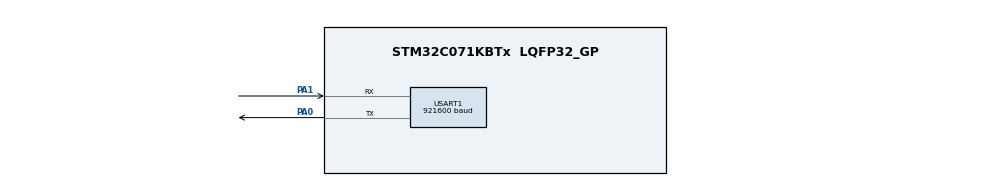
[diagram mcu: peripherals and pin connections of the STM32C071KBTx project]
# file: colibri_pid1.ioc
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Mcu.Family=STM32C0
Mcu.Name=STM32C071KBTx
Mcu.Package=LQFP32_GP
PA0.Mode=Asynchronous
PA0.Signal=USART1_TX
PA1.Mode=Asynchronous
PA1.Signal=USART1_RX
PA13.Mode=Serial_Wire
PA13.Signal=DEBUG_SWDIO
PA14-BOOT0.Mode=Serial_Wire
PA14-BOOT0.Signal=DEBUG_SWCLK
ProjectManager.HeapSize=0x200
ProjectManager.StackSize=0x400
ProjectManager.TargetToolchain=STM32CubeIDE
RCC.ADCFreq_Value=48000000
RCC.AHBFreq_Value=48000000
RCC.CortexFreq_Value=48000000
RCC.EXTERNAL_CLOCK_VALUE=12288000
RCC.HCLKFreq_Value=48000000
RCC.HSE_VALUE=8000000
RCC.HSI48_VALUE=48000000
RCC.HSISYSCLKDivider=RCC_HSI_DIV1
RCC.HSI_VALUE=48000000
RCC.LSE_VALUE=32768
RCC.SYSCLKFreq_VALUE=48000000
USART1.BaudRate=921600
USART1.VirtualMode-Asynchronous=VM_ASYNC
board=custom

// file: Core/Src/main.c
/* USER CODE BEGIN Header */
/**
  ******************************************************************************
  * @file           : main.c
  * @brief          : Main program body
  ******************************************************************************
  * @attention
  *
  * Copyright (c) 2026 STM32World <lth@stm32world.com>
  * All rights reserved.
  *
  * This software is licensed under terms that can be found in the LICENSE file
  * in the root directory of this software component.
  * If no LICENSE file comes with this software, it is provided AS-IS.
  *
  ******************************************************************************
  */
/* USER CODE END Header */
#include "main.h"

/* USER CODE BEGIN Includes */
#include <stdio.h>
/* USER CODE END Includes */

UART_HandleTypeDef huart1;

void SystemClock_Config(void);
static void MX_GPIO_Init(void);
static void MX_USART1_UART_Init(void);

int main(void)
{

  /* MCU Configuration--------------------------------------------------------*/

  /* Reset of all peripherals, Initializes the Flash interface and the Systick. */
  HAL_Init();

  /* Configure the system clock */
  SystemClock_Config();

  /* Initialize all configured peripherals */
  MX_GPIO_Init();
  MX_USART1_UART_Init();
  /* USER CODE BEGIN 2 */

  printf("Starting colibri pid1\n");

  /* USER CODE END 2 */

  /* Infinite loop */
  /* USER CODE BEGIN WHILE */

  uint32_t now, loop_cnt = 0, next_tick = 1000;

  while (1) {

      now = uwTick;

      if (now >= next_tick) {

          printf("Tick %lu (loop = %lu)\n", now / 1000, loop_cnt);

          loop_cnt = 0;
          next_tick = now + 1000;

      }

      ++loop_cnt;

    /* USER CODE END WHILE */

  }
}

void SystemClock_Config(void)
{
  RCC_OscInitTypeDef RCC_OscInitStruct = {0};
  RCC_ClkInitTypeDef RCC_ClkInitStruct = {0};

  __HAL_FLASH_SET_LATENCY(FLASH_LATENCY_1);

  /** Initializes the RCC Oscillators according to the specified parameters
  * in the RCC_OscInitTypeDef structure.
  */
  RCC_OscInitStruct.OscillatorType = RCC_OSCILLATORTYPE_HSI;
  RCC_OscInitStruct.HSIState = RCC_HSI_ON;
  RCC_OscInitStruct.HSIDiv = RCC_HSI_DIV1;
  RCC_OscInitStruct.HSICalibrationValue = RCC_HSICALIBRATION_DEFAULT;
  if (HAL_RCC_OscConfig(&RCC_OscInitStruct) != HAL_OK)
  {
    Error_Handler();
  }

  /** Initializes the CPU, AHB and APB buses clocks
  */
  RCC_ClkInitStruct.ClockType = RCC_CLOCKTYPE_HCLK|RCC_CLOCKTYPE_SYSCLK
                              |RCC_CLOCKTYPE_PCLK1;
  RCC_ClkInitStruct.SYSCLKSource = RCC_SYSCLKSOURCE_HSI;
  RCC_ClkInitStruct.SYSCLKDivider = RCC_SYSCLK_DIV1;
  RCC_ClkInitStruct.AHBCLKDivider = RCC_HCLK_DIV1;
  RCC_ClkInitStruct.APB1CLKDivider = RCC_APB1_DIV1;

  if (HAL_RCC_ClockConfig(&RCC_ClkInitStruct, FLASH_LATENCY_1) != HAL_OK)
  {
    Error_Handler();
  }
}

static void MX_USART1_UART_Init(void)
{

  huart1.Instance = USART1;
  huart1.Init.BaudRate = 921600;
  huart1.Init.WordLength = UART_WORDLENGTH_8B;
  huart1.Init.StopBits = UART_STOPBITS_1;
  huart1.Init.Parity = UART_PARITY_NONE;
  huart1.Init.Mode = UART_MODE_TX_RX;
  huart1.Init.HwFlowCtl = UART_HWCONTROL_NONE;
  huart1.Init.OverSampling = UART_OVERSAMPLING_16;
  huart1.Init.OneBitSampling = UART_ONE_BIT_SAMPLE_DISABLE;
  huart1.Init.ClockPrescaler = UART_PRESCALER_DIV1;
  huart1.AdvancedInit.AdvFeatureInit = UART_ADVFEATURE_NO_INIT;
  if (HAL_UART_Init(&huart1) != HAL_OK)
  {
    Error_Handler();
  }
  if (HAL_UARTEx_SetTxFifoThreshold(&huart1, UART_TXFIFO_THRESHOLD_1_8) != HAL_OK)
  {
    Error_Handler();
  }
  if (HAL_UARTEx_SetRxFifoThreshold(&huart1, UART_RXFIFO_THRESHOLD_1_8) != HAL_OK)
  {
    Error_Handler();
  }
  if (HAL_UARTEx_DisableFifoMode(&huart1) != HAL_OK)
  {
    Error_Handler();
  }

}

static void MX_GPIO_Init(void)
{

  /* GPIO Ports Clock Enable */
  __HAL_RCC_GPIOA_CLK_ENABLE();

}

/* USER CODE BEGIN 4 */

// Send printf to uart1
int __io_putchar(int ch) {
    if (ch == '\n') {
        HAL_UART_Transmit(&huart1, (uint8_t*)"\r", 1, HAL_MAX_DELAY);
    }
    if (HAL_UART_Transmit(&huart1, (uint8_t *)&ch, 1, HAL_MAX_DELAY) != HAL_OK) {
        return -1;
    }
    return ch;
}

/* USER CODE END 4 */

void Error_Handler(void)
{
  __disable_irq();
  while (1)
  {
  }
}
